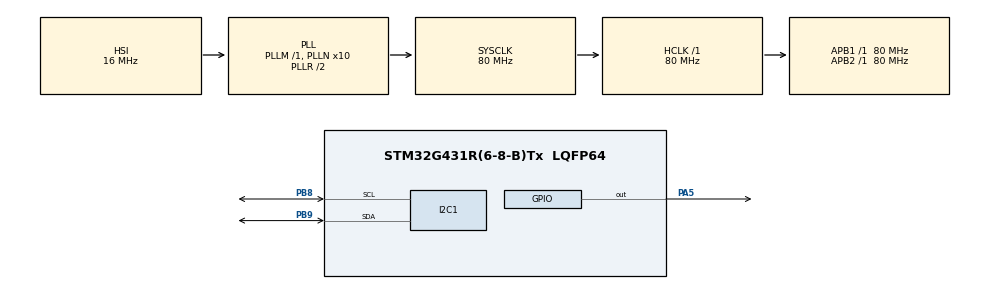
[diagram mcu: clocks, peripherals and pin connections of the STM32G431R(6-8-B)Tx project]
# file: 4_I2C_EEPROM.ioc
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I2C1.Timing=0x10909CEC
Mcu.Family=STM32G4
Mcu.Name=STM32G431R(6-8-B)Tx
Mcu.Package=LQFP64
NVIC.PriorityGroup=NVIC_PRIORITYGROUP_4
PA13.Mode=Serial_Wire
PA13.Signal=SYS_JTMS-SWDIO
PA14.Mode=Serial_Wire
PA14.Signal=SYS_JTCK-SWCLK
PA5.Signal=GPIO_Output
PB8-BOOT0.Mode=I2C
PB8-BOOT0.Signal=I2C1_SCL
PB9.Mode=I2C
PB9.Signal=I2C1_SDA
ProjectManager.HeapSize=0x200
ProjectManager.StackSize=0x400
ProjectManager.TargetToolchain=STM32CubeIDE
RCC.ADC12Freq_Value=80000000
RCC.AHBFreq_Value=80000000
RCC.APB1Freq_Value=80000000
RCC.APB1TimFreq_Value=80000000
RCC.APB2Freq_Value=80000000
RCC.APB2TimFreq_Value=80000000
RCC.CortexFreq_Value=80000000
RCC.EXTERNAL_CLOCK_VALUE=12288000
RCC.HCLKFreq_Value=80000000
RCC.HSE_VALUE=8000000
RCC.HSI48_VALUE=48000000
RCC.HSI_VALUE=16000000
RCC.LSE_VALUE=32768
RCC.PLLN=10
RCC.SYSCLKFreq_VALUE=80000000
RCC.SYSCLKSource=RCC_SYSCLKSOURCE_PLLCLK
RCC.USBFreq_Value=80000000
RCC.VCOOutputFreq_Value=160000000
board=custom

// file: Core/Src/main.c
/* USER CODE BEGIN Header */
/**
  ******************************************************************************
  * @file           : main.c
  * @brief          : Main program body
  ******************************************************************************
  * @attention
  *
  * Copyright (c) 2023 STMicroelectronics.
  * All rights reserved.
  *
  * This software is licensed under terms that can be found in the LICENSE file
  * in the root directory of this software component.
  * If no LICENSE file comes with this software, it is provided AS-IS.
  *
  ******************************************************************************
  */
/* USER CODE END Header */
#include "main.h"

/* USER CODE BEGIN PD */
#define EEPROM_ADDRESS             (0xA8)    /* EEPROM M24LR64 Address  */
#define EEPROM_PAGESIZE            (16)     /* EEPROM M24LR64 used     */
/* Maximum Timeout values for flags waiting loops. These timeouts are not based
   on accurate values, they just guarantee that the application will not remain
   stuck if the I2C communication is corrupted.
   You may modify these timeout values depending on CPU frequency and application
   conditions (interrupts routines ...). */
#define I2C_XFER_TIMEOUT_MAX      (300)
#define EEPROM_MAX_TRIALS         (3000U)

/* USER CODE END PD */

I2C_HandleTypeDef hi2c1;

/* USER CODE BEGIN PV */
/* Buffer used for transmission */
/* Size of Transmission buffer */
#define COUNTOF(__BUFFER__)   (sizeof(__BUFFER__) / sizeof(*(__BUFFER__)))
#define TXBUFFERSIZE                    (COUNTOF(aTxBuffer) - 1)
/* Size of Reception buffer */
#define RXBUFFERSIZE                    TXBUFFERSIZE

uint8_t aTxBuffer[] = "/* I2C HAL API EEPROM driver example: \
                        This firmware provides a basic example of how to use the I2C HAL API based and\
                        an associate I2C EEPROM driver to communicate with M24C02-FMC6TG EEPROM */";
uint8_t aRxBuffer[RXBUFFERSIZE];

/* USER CODE END PV */

void SystemClock_Config(void);
static void MX_GPIO_Init(void);
static void MX_I2C1_Init(void);
/* USER CODE BEGIN PFP */
static uint16_t Buffercmp(uint8_t* pBuffer1, uint8_t* pBuffer2, uint16_t BufferLength);

/* USER CODE END PFP */

/* USER CODE BEGIN 0 */
uint16_t Memory_Address;
int Remaining_Bytes;
__IO uint32_t I2C_Tx_Complete_Flag = 0;
__IO uint32_t I2C_Rx_Complete_Flag = 0;
__IO uint32_t I2C_Error_Flag = 0;

/* USER CODE END 0 */

int main(void)
{
  /* USER CODE BEGIN 1 */
	  uint32_t Memory_Write_Trials = 0;
	  uint32_t Memory_Read_Trials = 0;

  /* USER CODE END 1 */

  /* MCU Configuration--------------------------------------------------------*/

  /* Reset of all peripherals, Initializes the Flash interface and the Systick. */
  HAL_Init();

  /* Configure the system clock */
  SystemClock_Config();

  /* Initialize all configured peripherals */
  MX_GPIO_Init();
  MX_I2C1_Init();
  /* USER CODE BEGIN 2 */
  /* Initialize Remaining Bytes Value to TX Buffer Size */
    Remaining_Bytes = TXBUFFERSIZE;
    /* Initialize Memory address to 0 since EEPROM write will start from address 0 */
    Memory_Address = 0;

    while(Remaining_Bytes > 0)
    {
      do
      {
      /* Write EEPROM_PAGESIZE */
        if (HAL_I2C_Mem_Write(&hi2c1 , (uint16_t)EEPROM_ADDRESS, Memory_Address, I2C_MEMADD_SIZE_8BIT, (uint8_t*)(aTxBuffer + Memory_Address), EEPROM_PAGESIZE, 10000)!= HAL_OK)
        {
          if (HAL_I2C_GetError(&hi2c1) != HAL_I2C_ERROR_AF)
          {
            /* Writing process Error */
            Error_Handler();
          }
        }

        /* Increment Trials */
        Memory_Write_Trials++;
      }
      while((Memory_Write_Trials < EEPROM_MAX_TRIALS) && (HAL_I2C_GetError(&hi2c1) == HAL_I2C_ERROR_AF));

      /* Clear Trials */
      Memory_Write_Trials = 0;

      /* Wait for the end of the transfer */
      while (HAL_I2C_GetState(&hi2c1) != HAL_I2C_STATE_READY)
      {
      }

      /* Check if the EEPROM is ready for a new operation */
      while (HAL_I2C_IsDeviceReady(&hi2c1, EEPROM_ADDRESS, 10, 300) == HAL_TIMEOUT);
      /* Wait for the end of the transfer */
          while (HAL_I2C_GetState(&hi2c1) != HAL_I2C_STATE_READY)
          {
          }

          /* Update Remaining bytes and Memory Address values */
          Remaining_Bytes -= EEPROM_PAGESIZE;
          Memory_Address += EEPROM_PAGESIZE;
        }

        /*##-3- Start reading process ##############################################*/
        do
        {
          if(HAL_I2C_Mem_Read(&hi2c1 , (uint16_t)EEPROM_ADDRESS, 0, I2C_MEMADD_SIZE_8BIT, (uint8_t*)aRxBuffer, RXBUFFERSIZE, 10000)!= HAL_OK)
          {
            if (HAL_I2C_GetError(&hi2c1) != HAL_I2C_ERROR_AF)
            {
              /* Reading process Error */
              Error_Handler();
            }
          }

          /* Increment Trials */
          Memory_Read_Trials++;
        }
        while((Memory_Read_Trials < EEPROM_MAX_TRIALS) && (HAL_I2C_GetError(&hi2c1) == HAL_I2C_ERROR_AF));

        /* Clear Trials */
        Memory_Read_Trials = 0;

        /* Wait for the end of the transfer */
        while (HAL_I2C_GetState(&hi2c1) != HAL_I2C_STATE_READY)
        {
        }

        /*##-4- Compare the sent and received buffers ##############################*/
        if(Buffercmp((uint8_t*)aTxBuffer, (uint8_t*)aRxBuffer, RXBUFFERSIZE))
        {
          /* Processing Error */
          Error_Handler();
        }
  /* USER CODE END 2 */

  /* Infinite loop */
  /* USER CODE BEGIN WHILE */
  while (1)
  {
		HAL_GPIO_TogglePin(GPIOA, GPIO_PIN_5);
		HAL_Delay(100);

    /* USER CODE END WHILE */

  }
}

void SystemClock_Config(void)
{
  RCC_OscInitTypeDef RCC_OscInitStruct = {0};
  RCC_ClkInitTypeDef RCC_ClkInitStruct = {0};

  /** Configure the main internal regulator output voltage
  */
  HAL_PWREx_ControlVoltageScaling(PWR_REGULATOR_VOLTAGE_SCALE1);

  /** Initializes the RCC Oscillators according to the specified parameters
  * in the RCC_OscInitTypeDef structure.
  */
  RCC_OscInitStruct.OscillatorType = RCC_OSCILLATORTYPE_HSI;
  RCC_OscInitStruct.HSIState = RCC_HSI_ON;
  RCC_OscInitStruct.HSICalibrationValue = RCC_HSICALIBRATION_DEFAULT;
  RCC_OscInitStruct.PLL.PLLState = RCC_PLL_ON;
  RCC_OscInitStruct.PLL.PLLSource = RCC_PLLSOURCE_HSI;
  RCC_OscInitStruct.PLL.PLLM = RCC_PLLM_DIV1;
  RCC_OscInitStruct.PLL.PLLN = 10;
  RCC_OscInitStruct.PLL.PLLP = RCC_PLLP_DIV2;
  RCC_OscInitStruct.PLL.PLLQ = RCC_PLLQ_DIV2;
  RCC_OscInitStruct.PLL.PLLR = RCC_PLLR_DIV2;
  if (HAL_RCC_OscConfig(&RCC_OscInitStruct) != HAL_OK)
  {
    Error_Handler();
  }

  /** Initializes the CPU, AHB and APB buses clocks
  */
  RCC_ClkInitStruct.ClockType = RCC_CLOCKTYPE_HCLK|RCC_CLOCKTYPE_SYSCLK
                              |RCC_CLOCKTYPE_PCLK1|RCC_CLOCKTYPE_PCLK2;
  RCC_ClkInitStruct.SYSCLKSource = RCC_SYSCLKSOURCE_PLLCLK;
  RCC_ClkInitStruct.AHBCLKDivider = RCC_SYSCLK_DIV1;
  RCC_ClkInitStruct.APB1CLKDivider = RCC_HCLK_DIV1;
  RCC_ClkInitStruct.APB2CLKDivider = RCC_HCLK_DIV1;

  if (HAL_RCC_ClockConfig(&RCC_ClkInitStruct, FLASH_LATENCY_2) != HAL_OK)
  {
    Error_Handler();
  }
}

static void MX_I2C1_Init(void)
{

  hi2c1.Instance = I2C1;
  hi2c1.Init.Timing = 0x10909CEC;
  hi2c1.Init.OwnAddress1 = 0;
  hi2c1.Init.AddressingMode = I2C_ADDRESSINGMODE_7BIT;
  hi2c1.Init.DualAddressMode = I2C_DUALADDRESS_DISABLE;
  hi2c1.Init.OwnAddress2 = 0;
  hi2c1.Init.OwnAddress2Masks = I2C_OA2_NOMASK;
  hi2c1.Init.GeneralCallMode = I2C_GENERALCALL_DISABLE;
  hi2c1.Init.NoStretchMode = I2C_NOSTRETCH_DISABLE;
  if (HAL_I2C_Init(&hi2c1) != HAL_OK)
  {
    Error_Handler();
  }

  /** Configure Analogue filter
  */
  if (HAL_I2CEx_ConfigAnalogFilter(&hi2c1, I2C_ANALOGFILTER_ENABLE) != HAL_OK)
  {
    Error_Handler();
  }

  /** Configure Digital filter
  */
  if (HAL_I2CEx_ConfigDigitalFilter(&hi2c1, 0) != HAL_OK)
  {
    Error_Handler();
  }

}

static void MX_GPIO_Init(void)
{
  GPIO_InitTypeDef GPIO_InitStruct = {0};

  /* GPIO Ports Clock Enable */
  __HAL_RCC_GPIOA_CLK_ENABLE();
  __HAL_RCC_GPIOB_CLK_ENABLE();

  /*Configure GPIO pin Output Level */
  HAL_GPIO_WritePin(GPIOA, GPIO_PIN_5, GPIO_PIN_RESET);

  /*Configure GPIO pin : PA5 */
  GPIO_InitStruct.Pin = GPIO_PIN_5;
  GPIO_InitStruct.Mode = GPIO_MODE_OUTPUT_PP;
  GPIO_InitStruct.Pull = GPIO_NOPULL;
  GPIO_InitStruct.Speed = GPIO_SPEED_FREQ_LOW;
  HAL_GPIO_Init(GPIOA, &GPIO_InitStruct);

}

/* USER CODE BEGIN 4 */
static uint16_t Buffercmp(uint8_t* pBuffer1, uint8_t* pBuffer2, uint16_t BufferLength)
{
  while (BufferLength--)
  {
    if ((*pBuffer1) != *pBuffer2)
    {
      return BufferLength;
    }
    pBuffer1++;
    pBuffer2++;
  }

  return 0;
}

/* USER CODE END 4 */

void Error_Handler(void)
{
  __disable_irq();
  while (1)
  {
  }
}
